VERSION ""

NS_ :

BS_:

BU_: BMS Third_Party_Device

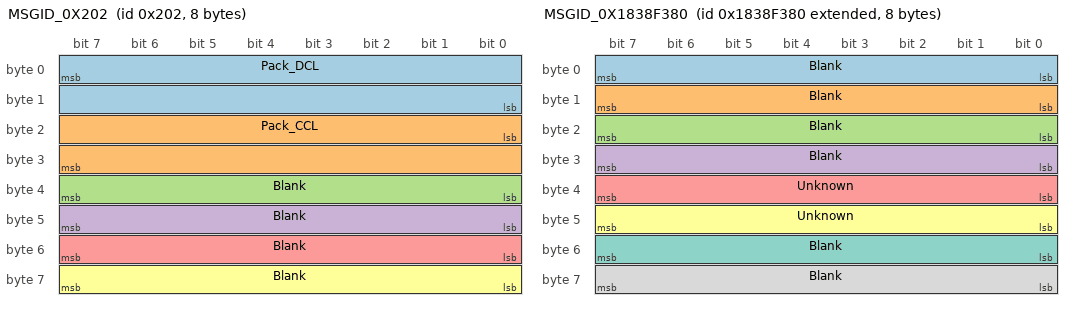
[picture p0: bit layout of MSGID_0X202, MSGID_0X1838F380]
BO_ 514 MSGID_0X202: 8 BMS
 SG_ Pack_DCL : 7|16@0+ (1.0,0) [0|0] "Amps"  Third_Party_Device
 SG_ Pack_CCL : 16|16@1+ (1.0,0) [0|0] "Amps"  Third_Party_Device
 SG_ Blank : 39|8@0+ (1.0,0) [0|0] ""  Third_Party_Device
 SG_ Blank : 47|8@0+ (1.0,0) [0|0] ""  Third_Party_Device
 SG_ Blank : 55|8@0+ (1.0,0) [0|0] ""  Third_Party_Device
 SG_ Blank : 63|8@0+ (1.0,1720) [0|0] ""  Third_Party_Device

BO_ 2553869184 MSGID_0X1838F380: 8 Third_Party_Device
 SG_ Blank : 7|8@0+ (1.0,0) [0|0] ""  BMS
 SG_ Blank : 15|8@0+ (1.0,0) [0|0] ""  BMS
 SG_ Blank : 23|8@0+ (1.0,0) [0|0] ""  BMS
 SG_ Blank : 31|8@0+ (1.0,0) [0|0] ""  BMS
 SG_ Unknown : 39|8@0+ (1.0,0) [0|0] ""  BMS
 SG_ Unknown : 47|8@0+ (1.0,0) [0|0] ""  BMS
 SG_ Blank : 55|8@0+ (1.0,0) [0|0] ""  BMS
 SG_ Blank : 63|8@0+ (1.0,1721) [0|0] ""  BMS

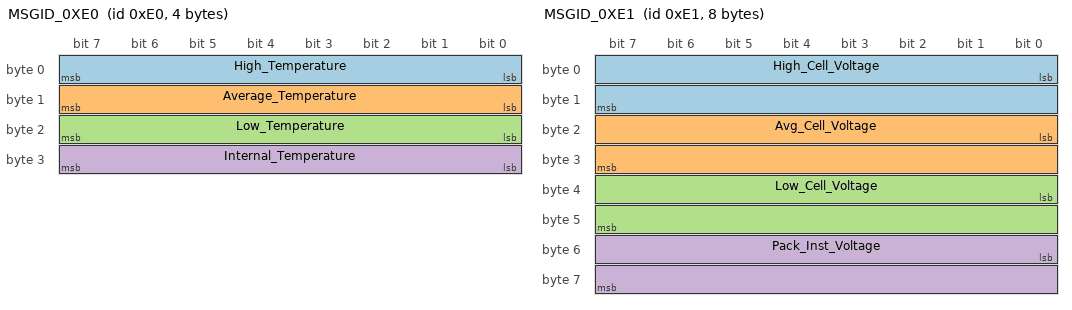
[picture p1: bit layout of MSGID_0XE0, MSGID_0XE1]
BO_ 224 MSGID_0XE0: 4 BMS
 SG_ High_Temperature : 7|8@0+ (1.0,0) [0|0] "Celsius"  Third_Party_Device
 SG_ Average_Temperature : 15|8@0+ (1.0,0) [0|0] "Celsius"  Third_Party_Device
 SG_ Low_Temperature : 23|8@0+ (1.0,0) [0|0] "Celsius"  Third_Party_Device
 SG_ Internal_Temperature : 31|8@0+ (1.0,0) [0|0] "Celsius"  Third_Party_Device

BO_ 225 MSGID_0XE1: 8 BMS
 SG_ High_Cell_Voltage : 0|16@1+ (1.0E-4,0) [0|0] "Volts"  Third_Party_Device
 SG_ Avg_Cell_Voltage : 16|16@1+ (1.0E-4,0) [0|0] "Volts"  Third_Party_Device
 SG_ Low_Cell_Voltage : 32|16@1+ (1.0E-4,0) [0|0] "Volts"  Third_Party_Device
 SG_ Pack_Inst_Voltage : 48|16@1+ (0.1,0) [0|0] "Volts"  Third_Party_Device

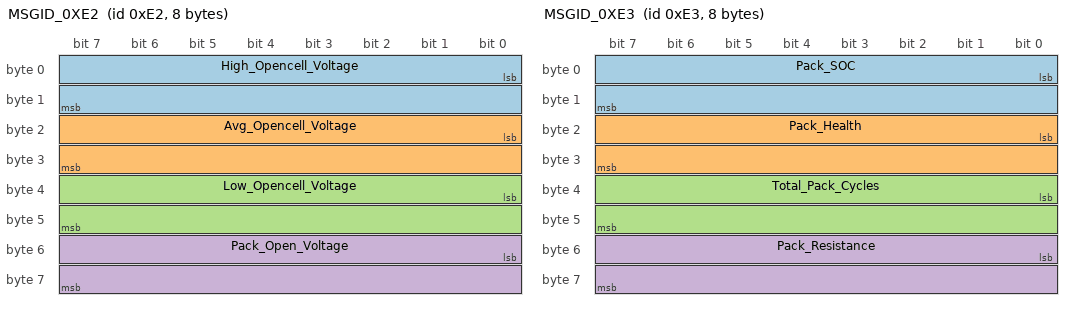
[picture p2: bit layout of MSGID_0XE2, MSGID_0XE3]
BO_ 226 MSGID_0XE2: 8 BMS
 SG_ High_Opencell_Voltage : 0|16@1+ (1.0E-4,0) [0|0] "Volts"  Third_Party_Device
 SG_ Avg_Opencell_Voltage : 16|16@1+ (1.0E-4,0) [0|0] "Volts"  Third_Party_Device
 SG_ Low_Opencell_Voltage : 32|16@1+ (1.0E-4,0) [0|0] "Volts"  Third_Party_Device
 SG_ Pack_Open_Voltage : 48|16@1+ (0.1,0) [0|0] "Volts"  Third_Party_Device

BO_ 227 MSGID_0XE3: 8 BMS
 SG_ Pack_SOC : 0|16@1+ (0.5,0) [0|0] "Percent"  Third_Party_Device
 SG_ Pack_Health : 16|16@1+ (1.0,0) [0|0] "Percent"  Third_Party_Device
 SG_ Total_Pack_Cycles : 32|16@1+ (1.0,0) [0|0] "Num"  Third_Party_Device
 SG_ Pack_Resistance : 48|16@1+ (0.001,0) [0|0] "Ohms"  Third_Party_Device

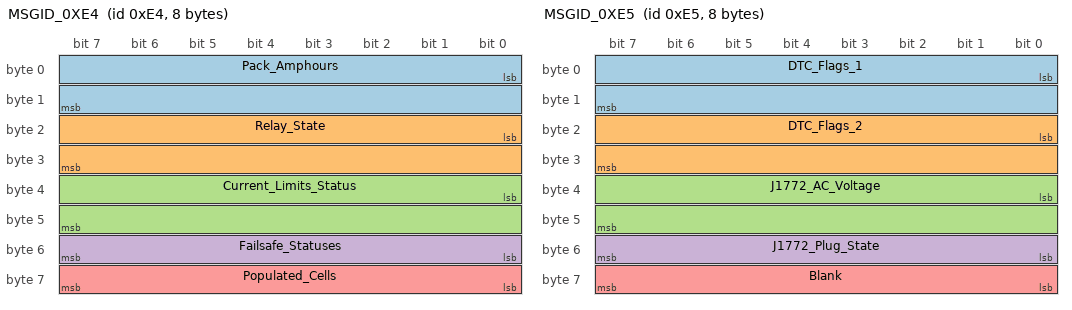
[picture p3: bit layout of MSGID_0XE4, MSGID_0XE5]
BO_ 228 MSGID_0XE4: 8 BMS
 SG_ Pack_Amphours : 0|16@1+ (0.1,0) [0|0] "Amphours"  Third_Party_Device
 SG_ Relay_State : 16|16@1+ (1.0,0) [0|0] ""  Third_Party_Device
 SG_ Current_Limits_Status : 32|16@1+ (1.0,0) [0|0] ""  Third_Party_Device
 SG_ Failsafe_Statuses : 55|8@0+ (1.0,0) [0|0] ""  Third_Party_Device
 SG_ Populated_Cells : 63|8@0+ (1.0,0) [0|0] "Num"  Third_Party_Device

BO_ 229 MSGID_0XE5: 8 BMS
 SG_ DTC_Flags_1 : 0|16@1+ (1.0,0) [0|0] ""  Third_Party_Device
 SG_ DTC_Flags_2 : 16|16@1+ (1.0,0) [0|0] ""  Third_Party_Device
 SG_ J1772_AC_Voltage : 32|16@1+ (0.1,0) [0|0] "Volts"  Third_Party_Device
 SG_ J1772_Plug_State : 55|8@0+ (1.0,0) [0|0] ""  Third_Party_Device
 SG_ Blank : 63|8@0+ (1.0,0) [0|0] ""  Third_Party_Device

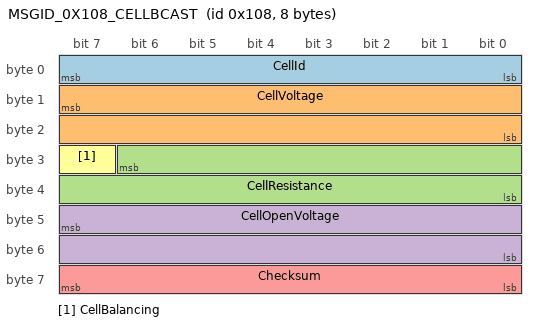
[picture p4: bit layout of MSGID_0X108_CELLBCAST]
BO_ 264 MSGID_0X108_CELLBCAST: 8 BMS
 SG_ CellId : 7|8@0+ (1,0) [0|0] "#" Third_Party_Device
 SG_ CellVoltage : 15|16@0+ (0.0001,0) [0|0] "Volts" Third_Party_Device
 SG_ CellResistance : 30|15@0+ (0.01,0) [0|0] "mOhms" Third_Party_Device
 SG_ CellOpenVoltage : 47|16@0+ (0.0001,0) [0|0] "Volts" Third_Party_Device
 SG_ Checksum : 63|8@0+ (1,0) [0|0] "" Third_Party_Device
 SG_ CellBalancing : 31|1@1+ (1,0) [0|0] "" Third_Party_Device
CM_ BO_ 514 "This ID Transmits at 96 ms.";
CM_ BO_ 224 "This ID Transmits at 504 ms.";
CM_ BO_ 225 "This ID Transmits at 504 ms.";
CM_ BO_ 226 "This ID Transmits at 504 ms.";
CM_ BO_ 227 "This ID Transmits at 504 ms.";
CM_ BO_ 228 "This ID Transmits at 504 ms.";
CM_ BO_ 229 "This ID Transmits at 504 ms.";
CM_ BO_ 264 "This ID Transmits at 100 ms.";
CM_ SG_ 264 Checksum "Value = (0x108 + 8 + byte0 + byte1 + ... + byte6) & 0xFF";
